VERSION ""

NS_ :

BS_:

BU_: FrontBoard BackBoard Kvaser SteeringWheel

BO_ 3221225472 VECTOR__INDEPENDENT_SIG_MSG: 0 Vector__XXX
 SG_ NewSignal_0009 : 0|8@1+ (1,0) [0|0] "" Vector__XXX

BO_ 259 FrontAnalog: 16 FrontBoard
 SG_ Analog1 : 0|16@1+ (1,0) [0|0] ""  FrontBoard,Kvaser,SteeringWheel
 SG_ Analog2 : 16|16@1+ (1,0) [0|0] ""  FrontBoard,Kvaser,SteeringWheel
 SG_ Analog3 : 32|16@1+ (1,0) [0|0] ""  FrontBoard,Kvaser,SteeringWheel
 SG_ Analog4 : 48|16@1+ (1,0) [0|0] ""  FrontBoard,Kvaser,SteeringWheel
 SG_ Analog5 : 64|16@1+ (1,0) [0|0] ""  FrontBoard,Kvaser,SteeringWheel
 SG_ Analog6 : 80|16@1+ (1,0) [0|0] ""  FrontBoard,Kvaser,SteeringWheel
 SG_ Analog7 : 96|16@1+ (1,0) [0|0] ""  FrontBoard,Kvaser,SteeringWheel
 SG_ Analog8 : 112|16@1+ (1,0) [0|0] ""  FrontBoard,Kvaser,SteeringWheel

BO_ 258 RearAnalog: 16 BackBoard
 SG_ Analog1 : 0|16@1+ (1,0) [0|0] ""  BackBoard,Kvaser,SteeringWheel
 SG_ Analog2 : 16|16@1+ (1,0) [0|0] ""  BackBoard,Kvaser,SteeringWheel
 SG_ Analog3 : 32|16@1+ (1,0) [0|0] ""  BackBoard,Kvaser,SteeringWheel
 SG_ Analog4 : 48|16@1+ (1,0) [0|0] ""  BackBoard,Kvaser,SteeringWheel
 SG_ Analog5 : 64|16@1+ (1,0) [0|0] ""  BackBoard,Kvaser,SteeringWheel
 SG_ Analog6 : 80|16@1+ (1,0) [0|0] ""  BackBoard,Kvaser,SteeringWheel
 SG_ Analog7 : 96|16@1+ (1,0) [0|0] ""  BackBoard,Kvaser,SteeringWheel
 SG_ Analog8 : 112|16@1+ (1,0) [0|0] ""  BackBoard,Kvaser,SteeringWheel

BO_ 257 FrontFrequency: 16 FrontBoard
 SG_ Frequency1 : 0|32@1+ (1,0) [0|0] ""  FrontBoard,Kvaser,SteeringWheel
 SG_ Frequency2 : 32|32@1+ (1,0) [0|0] ""  FrontBoard,Kvaser,SteeringWheel
 SG_ Frequency3 : 64|32@1+ (1,0) [0|0] ""  FrontBoard,Kvaser,SteeringWheel
 SG_ Frequency4 : 96|32@1+ (1,0) [0|0] ""  FrontBoard,Kvaser,SteeringWheel

BO_ 256 RearFrequency: 16 BackBoard
 SG_ Frequency1 : 0|32@1+ (1,0) [0|0] ""  BackBoard,Kvaser,SteeringWheel
 SG_ Frequency2 : 32|32@1+ (1,0) [0|0] ""  BackBoard,Kvaser,SteeringWheel
 SG_ Frequency3 : 64|32@1+ (1,0) [0|0] ""  BackBoard,Kvaser,SteeringWheel
 SG_ Frequency4 : 96|32@1+ (1,0) [0|0] ""  BackBoard,Kvaser,SteeringWheel

BO_ 1536 FrontAero: 16 FrontBoard
 SG_ Pressure1 : 0|24@1- (1,0) [0|0] ""  FrontBoard,Kvaser,SteeringWheel
 SG_ Pressure2 : 24|24@1- (1,0) [0|0] ""  FrontBoard,Kvaser,SteeringWheel
 SG_ Pressure3 : 48|24@1- (1,0) [0|0] ""  FrontBoard,Kvaser,SteeringWheel
 SG_ Temperature1 : 72|16@1- (1,0) [0|0] ""  FrontBoard,Kvaser,SteeringWheel
 SG_ Temperature2 : 88|16@1- (1,0) [0|0] ""  FrontBoard,Kvaser,SteeringWheel
 SG_ Temperature3 : 104|16@1- (1,0) [0|0] ""  FrontBoard,Kvaser,SteeringWheel

BO_ 1537 RearAero: 16 BackBoard
 SG_ Pressure1 : 0|24@1- (1,0) [0|0] ""  BackBoard,SteeringWheel,Kvaser
 SG_ Pressure2 : 24|24@1- (1,0) [0|0] ""  BackBoard,SteeringWheel,Kvaser
 SG_ Pressure3 : 48|24@1- (1,0) [0|0] ""  BackBoard,SteeringWheel,Kvaser
 SG_ Temperature1 : 72|16@1- (1,0) [0|0] ""  BackBoard,SteeringWheel,Kvaser
 SG_ Temperature2 : 88|16@1- (1,0) [0|0] ""  BackBoard,SteeringWheel,Kvaser
 SG_ Temperature3 : 104|16@1- (1,0) [0|0] ""  BackBoard,SteeringWheel,Kvaser

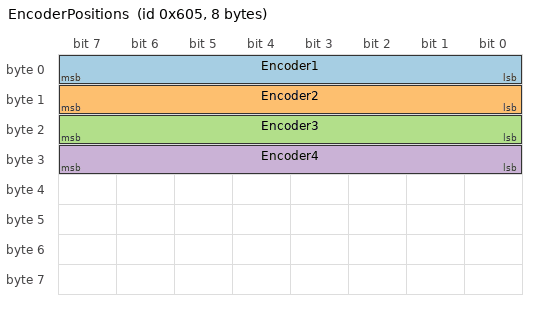
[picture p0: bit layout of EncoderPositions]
BO_ 1541 EncoderPositions: 8 SteeringWheel
 SG_ Encoder1 : 0|8@1+ (1,0) [0|0] ""  Kvaser
 SG_ Encoder2 : 8|8@1+ (1,0) [0|0] ""  Kvaser
 SG_ Encoder3 : 16|8@1+ (1,0) [0|0] ""  Kvaser
 SG_ Encoder4 : 24|8@1+ (1,0) [0|0] ""  Kvaser

BO_ 1552 FrontStrainGauges1: 20 FrontBoard
 SG_ Gauge1 : 0|24@1+ (1,0) [0|0] "" Vector__XXX
 SG_ Gauge2 : 24|24@1+ (1,0) [0|0] "" Vector__XXX
 SG_ Gauge3 : 48|24@1+ (1,0) [0|0] "" Vector__XXX
 SG_ Gauge4 : 72|24@1+ (1,0) [0|0] "" Vector__XXX
 SG_ Gauge5 : 96|24@1+ (1,0) [0|0] "" Vector__XXX
 SG_ Gauge6 : 120|24@1+ (1,0) [0|0] "" Vector__XXX

BO_ 1553 FrontStrainGauges2: 20 FrontBoard
 SG_ Gauge1 : 0|24@1+ (1,0) [0|0] "" Vector__XXX
 SG_ Gauge2 : 24|24@1+ (1,0) [0|0] "" Vector__XXX
 SG_ Gauge3 : 48|24@1+ (1,0) [0|0] "" Vector__XXX
 SG_ Gauge4 : 72|24@1+ (1,0) [0|0] "" Vector__XXX
 SG_ Gauge5 : 96|24@1+ (1,0) [0|0] "" Vector__XXX
 SG_ Gauge6 : 120|24@1+ (1,0) [0|0] "" Vector__XXX

BO_ 1554 RearStrainGauges1: 20 BackBoard
 SG_ Gauge1 : 0|24@1+ (1,0) [0|0] "" Vector__XXX
 SG_ Gauge2 : 24|24@1+ (1,0) [0|0] "" Vector__XXX
 SG_ Gauge3 : 48|24@1+ (1,0) [0|0] "" Vector__XXX
 SG_ Gauge4 : 72|24@1+ (1,0) [0|0] "" Vector__XXX
 SG_ Gauge5 : 96|24@1+ (1,0) [0|0] "" Vector__XXX
 SG_ Gauge6 : 120|24@1+ (1,0) [0|0] "" Vector__XXX

BO_ 1555 RearStrainGauges2: 20 BackBoard
 SG_ Gauge1 : 0|24@1+ (1,0) [0|0] "" Vector__XXX
 SG_ Gauge2 : 24|24@1+ (1,0) [0|0] "" Vector__XXX
 SG_ Gauge3 : 48|24@1+ (1,0) [0|0] "" Vector__XXX
 SG_ Gauge4 : 72|24@1+ (1,0) [0|0] "" Vector__XXX
 SG_ Gauge5 : 96|24@1+ (1,0) [0|0] "" Vector__XXX
 SG_ Gauge6 : 120|24@1+ (1,0) [0|0] "" Vector__XXX

BO_ 100 GPSBestPos: 64 Vector__XXX
 SG_ NewSignal_0001 : 0|32@1+ (1,0) [0|0] "" Vector__XXX

BA_DEF_  "BusType" STRING ;
BA_DEF_ BO_  "VFrameFormat" ENUM  "StandardCAN","ExtendedCAN","reserved","reserved","reserved","reserved","reserved","reserved","reserved","reserved","reserved","reserved","reserved","reserved","StandardCAN_FD","ExtendedCAN_FD";
BA_DEF_DEF_  "BusType" "";
BA_DEF_DEF_  "VFrameFormat" "StandardCAN";
BA_ "BusType" "CAN FD";
BA_ "VFrameFormat" BO_ 259 14;
BA_ "VFrameFormat" BO_ 258 14;
BA_ "VFrameFormat" BO_ 257 14;
BA_ "VFrameFormat" BO_ 256 14;
BA_ "VFrameFormat" BO_ 1536 14;
BA_ "VFrameFormat" BO_ 1537 14;
BA_ "VFrameFormat" BO_ 1541 14;
BA_ "VFrameFormat" BO_ 1552 14;
BA_ "VFrameFormat" BO_ 1553 14;
BA_ "VFrameFormat" BO_ 1554 14;
BA_ "VFrameFormat" BO_ 1555 14;
BA_ "VFrameFormat" BO_ 100 14;
